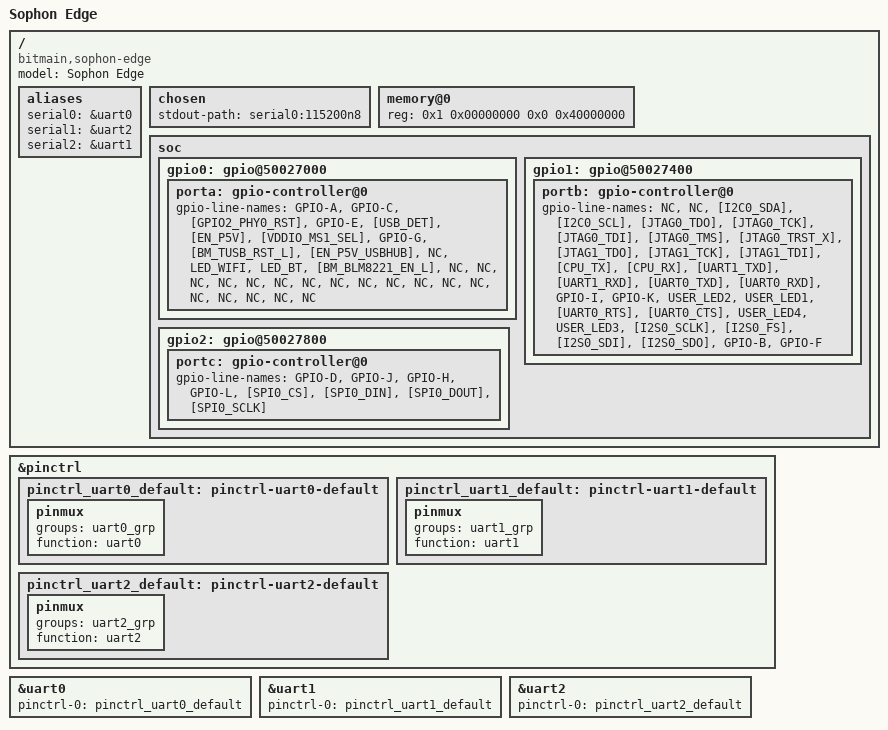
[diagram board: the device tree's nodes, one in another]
/dts-v1/;
#include "bm1880.dtsi"
/ {
	compatible = "bitmain,sophon-edge", "bitmain,bm1880";
	model = "Sophon Edge";
	aliases {
		serial0 = &uart0;
		serial1 = &uart2;
		serial2 = &uart1;
	};
	chosen {
		stdout-path = "serial0:115200n8";
	};
	memory@0 {
		device_type = "memory";
		reg = <0x1 0x00000000 0x0 0x40000000>;  
	};
	soc {
		gpio0: gpio@50027000 {
			porta: gpio-controller@0 {
				gpio-line-names =
					"GPIO-A",  
					"GPIO-C",  
					"[GPIO2_PHY0_RST]",  
					"GPIO-E",  
					"[USB_DET]",  
					"[EN_P5V]",  
					"[VDDIO_MS1_SEL]",  
					"GPIO-G",  
					"[BM_TUSB_RST_L]",  
					"[EN_P5V_USBHUB]",  
					"NC",
					"LED_WIFI",  
					"LED_BT",  
					"[BM_BLM8221_EN_L]",  
					"NC",  
					"NC",  
					"NC",  
					"NC",  
					"NC",  
					"NC",  
					"NC",  
					"NC",  
					"NC",  
					"NC",  
					"NC",  
					"NC",  
					"NC",  
					"NC",  
					"NC",  
					"NC",  
					"NC",  
					"NC";  
			};
		};
		gpio1: gpio@50027400 {
			portb: gpio-controller@0 {
				gpio-line-names =
					"NC",  
					"NC",  
					"[I2C0_SDA]",  
					"[I2C0_SCL]",  
					"[JTAG0_TDO]",  
					"[JTAG0_TCK]",  
					"[JTAG0_TDI]",  
					"[JTAG0_TMS]",  
					"[JTAG0_TRST_X]",  
					"[JTAG1_TDO]",  
					"[JTAG1_TCK]",  
					"[JTAG1_TDI]",  
					"[CPU_TX]",  
					"[CPU_RX]",  
					"[UART1_TXD]",  
					"[UART1_RXD]",  
					"[UART0_TXD]",  
					"[UART0_RXD]",  
					"GPIO-I",  
					"GPIO-K",  
					"USER_LED2",  
					"USER_LED1",  
					"[UART0_RTS]",  
					"[UART0_CTS]",  
					"USER_LED4",  
					"USER_LED3",  
					"[I2S0_SCLK]",  
					"[I2S0_FS]",  
					"[I2S0_SDI]",  
					"[I2S0_SDO]",  
					"GPIO-B",  
					"GPIO-F";  
			};
		};
		gpio2: gpio@50027800 {
			portc: gpio-controller@0 {
				gpio-line-names =
					"GPIO-D",  
					"GPIO-J",  
					"GPIO-H",  
					"GPIO-L",  
					"[SPI0_CS]",  
					"[SPI0_DIN]",  
					"[SPI0_DOUT]",  
					"[SPI0_SCLK]";  
			};
		};
	};
};
&pinctrl {
	pinctrl_uart0_default: pinctrl-uart0-default {
		pinmux {
			groups = "uart0_grp";
			function = "uart0";
		};
	};
	pinctrl_uart1_default: pinctrl-uart1-default {
		pinmux {
			groups = "uart1_grp";
			function = "uart1";
		};
	};
	pinctrl_uart2_default: pinctrl-uart2-default {
		pinmux {
			groups = "uart2_grp";
			function = "uart2";
		};
	};
};
&uart0 {
	status = "okay";
	pinctrl-names = "default";
	pinctrl-0 = <&pinctrl_uart0_default>;
};
&uart1 {
	status = "okay";
	pinctrl-names = "default";
	pinctrl-0 = <&pinctrl_uart1_default>;
};
&uart2 {
	status = "okay";
	pinctrl-names = "default";
	pinctrl-0 = <&pinctrl_uart2_default>;
};
